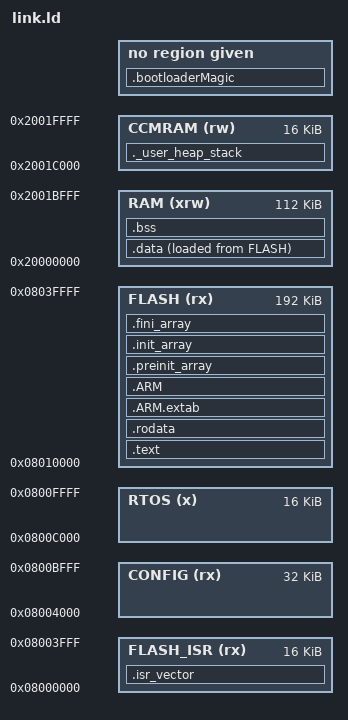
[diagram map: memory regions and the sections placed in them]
ENTRY(Reset_Handler)

/* Highest address of the user mode stack */
_estack = 0x2001FFFF;    /* end of RAM, in CCM space. */

/* Generate a link error if heap and stack don't fit into RAM */
_Min_Heap_Size = 0x1000;      /* required amount of heap  */
_Min_Stack_Size = 0x1000;     /* required amount of stack */

/* Flash is organised into 4 16Kb sectors, 1 64Kb sector, followed
by 128Kb sectors. We need to hijack two of the 16Kb sectors to store
configuration into, thus wasting most of the initial ISR sector.*/
MEMORY
{
FLASH_ISR (rx)  : ORIGIN = 0x08000000, LENGTH = 16K
CONFIG (rx)     : ORIGIN = 0x08004000, LENGTH = 32K
RTOS (x)        : ORIGIN = 0x0800C000, LENGTH = 16K
FLASH (rx)      : ORIGIN = 0x08010000, LENGTH = 192K
RAM (xrw)       : ORIGIN = 0x20000000, LENGTH = 112K

/* NOT DMA Capable.  We hope the DMA remains at the top of the RAM area.
This means - DO NOT DO ANY DMA FROM THE STACK. */
CCMRAM (rw)     : ORIGIN = 0x2001C000, LENGTH = 16K
}

/* Define output sections */
SECTIONS
{
  /* The startup code goes first into FLASH */
  .isr_vector :
  {
    . = ALIGN(4);
    KEEP(*(.isr_vector)) /* Startup code */
    . = ALIGN(4);
  } >FLASH_ISR

  /* The program code and other data goes into FLASH */
  .text :
  {
    . = ALIGN(4);
    *(.text)           /* .text sections (code) */
    *(.text*)          /* .text* sections (code) */
    *(.glue_7)         /* glue arm to thumb code */
    *(.glue_7t)        /* glue thumb to arm code */
    *(.eh_frame)

    KEEP (*(.init))
    KEEP (*(.fini))

    . = ALIGN(4);
    _etext = .;        /* define a global symbols at end of code */
  } >FLASH

  /* Constant data goes into FLASH */
  .rodata :
  {
    . = ALIGN(4);
    *(.rodata)         /* .rodata sections (constants, strings, etc.) */
    *(.rodata*)        /* .rodata* sections (constants, strings, etc.) */
    . = ALIGN(4);
  } >FLASH

  .ARM.extab   : { *(.ARM.extab* .gnu.linkonce.armextab.*) } >FLASH
  .ARM : {
    __exidx_start = .;
    *(.ARM.exidx*)
    __exidx_end = .;
  } >FLASH

  .preinit_array     :
  {
    PROVIDE_HIDDEN (__preinit_array_start = .);
    KEEP (*(.preinit_array*))
    PROVIDE_HIDDEN (__preinit_array_end = .);
  } >FLASH
  .init_array :
  {
    PROVIDE_HIDDEN (__init_array_start = .);
    KEEP (*(SORT(.init_array.*)))
    KEEP (*(.init_array*))
    PROVIDE_HIDDEN (__init_array_end = .);
  } >FLASH
  .fini_array :
  {
    PROVIDE_HIDDEN (__fini_array_start = .);
    KEEP (*(SORT(.fini_array.*)))
    KEEP (*(.fini_array*))
    PROVIDE_HIDDEN (__fini_array_end = .);
  } >FLASH

  /* used by the startup to initialize data */
  _sidata = LOADADDR(.data);

  /* Initialized data sections goes into RAM, load LMA copy after code */
  .data : 
  {
    . = ALIGN(4);
    _sdata = .;        /* create a global symbol at data start */
    *(.data)           /* .data sections */
    *(.data*)          /* .data* sections */

    . = ALIGN(4);
    _edata = .;        /* define a global symbol at data end */
  } >RAM AT> FLASH

  .bootloaderMagic :
  {
    . = ALIGN(4);
    *(.bootloaderMagic)
  }

  
  /* Uninitialized data section */
  . = ALIGN(4);
  .bss :
  {
    /* This is used by the startup in order to initialize the .bss secion */
    _sbss = .;         /* define a global symbol at bss start */
    __bss_start__ = _sbss;
    *(.bss)
    *(.bss*)
    *(COMMON)

    . = ALIGN(4);
    _ebss = .;         /* define a global symbol at bss end */
    __bss_end__ = _ebss;
  } >RAM

  /* User_heap_stack section, used to check that there is enough RAM left */
  ._user_heap_stack :
  {
    . = ALIGN(4);
    PROVIDE ( end = . );
    PROVIDE ( _end = . );
    . = . + _Min_Heap_Size;
    . = . + _Min_Stack_Size;
    . = ALIGN(4);
  } >CCMRAM

  

  /* Remove information from the standard libraries */
  /DISCARD/ :
  {
    libc.a ( * )
    libm.a ( * )
    libgcc.a ( * )
  }

  .ARM.attributes 0 : { *(.ARM.attributes) }

}
